# ESP32-C2 register map
Vendor: ESPRESSIF SYSTEMS (SHANGHAI) CO., LTD.; Series: ESP32 C-Series; File version: 11
CPU: RV32IMC r0p0, little endian, no MPU, no FPU, 0 interrupt priority bits
Address unit: 32 bits
Registers are 32-bit, read-write, reset 0x0 unless marked. A register's access mark holds for its fields unless they carry their own. Offsets are from the block's base; [hi:lo] are bit positions.

## ASSIST_DEBUG — Debug Assist
Base 0x600CE000
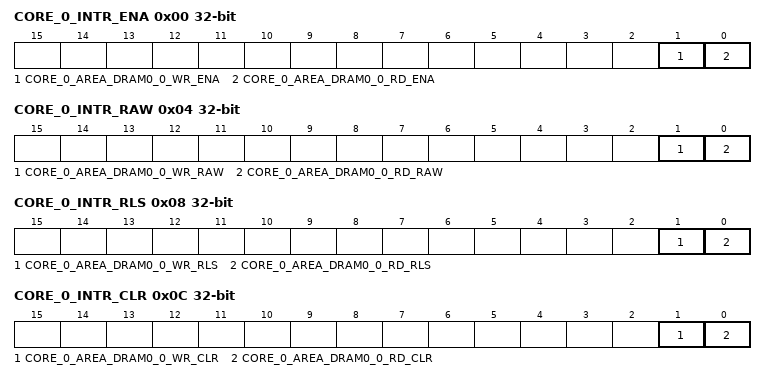
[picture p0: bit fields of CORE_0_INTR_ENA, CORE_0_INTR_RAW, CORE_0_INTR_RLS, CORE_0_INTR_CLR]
0x00 CORE_0_INTR_ENA — core0 monitor enable configuration register
  [1] CORE_0_AREA_DRAM0_0_WR_ENA — enbale sp overflow monitor
  [0] CORE_0_AREA_DRAM0_0_RD_ENA — enbale sp underlow monitor
0x04 CORE_0_INTR_RAW ro — core0 monitor interrupt status register
  [1] CORE_0_AREA_DRAM0_0_WR_RAW — sp overflow monitor interupt status register
  [0] CORE_0_AREA_DRAM0_0_RD_RAW — sp underlow monitor interrupt status register
0x08 CORE_0_INTR_RLS — core0 monitor interrupt enable register
  [1] CORE_0_AREA_DRAM0_0_WR_RLS — enbale sp overflow monitor interrupt
  [0] CORE_0_AREA_DRAM0_0_RD_RLS — enbale sp underlow monitor interrupt
0x0C CORE_0_INTR_CLR wo — core0 monitor interrupt clr register
  [1] CORE_0_AREA_DRAM0_0_WR_CLR — clr sp overflow monitor interrupt
  [0] CORE_0_AREA_DRAM0_0_RD_CLR — clr sp underlow monitor interrupt
0x10 CORE_0_SP_MIN — stack min value
  [31:0] CORE_0_SP_MIN — core0 sp region configuration regsiter
0x14 CORE_0_SP_MAX reset 0xFFFFFFFF — stack max value
  [31:0] CORE_0_SP_MAX — core0 sp pc status register
0x18 CORE_0_SP_PC ro — stack monitor pc status register
  [31:0] CORE_0_SP_PC — This regsiter stores the PC when trigger stack monitor.
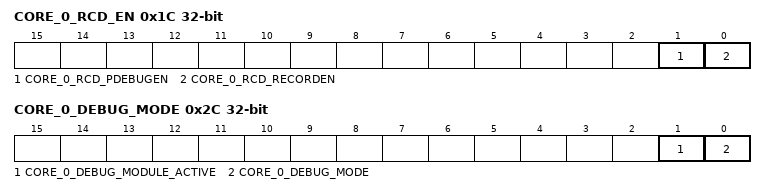
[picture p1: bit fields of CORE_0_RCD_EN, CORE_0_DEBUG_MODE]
0x1C CORE_0_RCD_EN — record enable configuration register
  [1] CORE_0_RCD_PDEBUGEN — Set 1 to enable cpu pdebug function, must set this bit can get cpu PC
  [0] CORE_0_RCD_RECORDEN — Set 1 to enable record PC
0x20 CORE_0_RCD_PDEBUGPC ro — record status regsiter
  [31:0] CORE_0_RCD_PDEBUGPC — recorded PC
0x24 CORE_0_RCD_PDEBUGSP ro — record status regsiter
  [31:0] CORE_0_RCD_PDEBUGSP — recorded sp
0x28 CORE_0_LASTPC_BEFORE_EXCEPTION ro — cpu status register
  [31:0] CORE_0_LASTPC_BEFORE_EXC — cpu's lastpc before exception
0x2C CORE_0_DEBUG_MODE ro — cpu status register
  [1] CORE_0_DEBUG_MODULE_ACTIVE — cpu debug_module active status
  [0] CORE_0_DEBUG_MODE — cpu debug mode status, 1 means cpu enter debug mode.
0x30 CLOCK_GATE reset 0x1
  [0] CLK_EN
0x1FC DATE reset 0x2106020 — version register
  [27:0] DATE

## BB — BB Peripheral
Base 0x6001D000
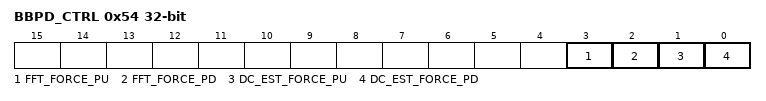
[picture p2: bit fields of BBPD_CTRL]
0x54 BBPD_CTRL — Baseband control register
  [3] FFT_FORCE_PU, [2] FFT_FORCE_PD, [1] DC_EST_FORCE_PU, [0] DC_EST_FORCE_PD

## ECC — ECC (ECC Hardware Accelerator)
Base 0x6003E000
0x0C MULT_INT_RAW ro — I2S interrupt raw register, valid in level.
  [0] CALC_DONE_INT_RAW — The raw interrupt status bit for the i2s_tx_hung_int interrupt
0x10 MULT_INT_ST ro — I2S interrupt status register.
  [0] CALC_DONE_INT_ST — The masked interrupt status bit for the i2s_rx_done_int interrupt
0x14 MULT_INT_ENA — I2S interrupt enable register.
  [0] CALC_DONE_INT_ENA — The interrupt enable bit for the i2s_rx_done_int interrupt
0x18 MULT_INT_CLR wo — I2S interrupt clear register.
  [0] CALC_DONE_INT_CLR — Set this bit to clear the i2s_rx_done_int interrupt
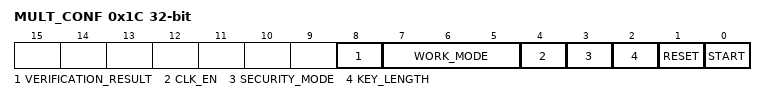
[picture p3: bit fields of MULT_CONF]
0x1C MULT_CONF access per field — I2S RX configure register
  [8] VERIFICATION_RESULT ro — Represents the verification result of ECC Accelerator, valid only when calculation is done.
  [7:5] WORK_MODE rw — Configures the work mode of ECC Accelerator.
  [4] CLK_EN rw — Configures whether to force on register clock gate.
  [3] SECURITY_MODE rw — Configures the security mode of ECC Accelerator.
  [2] KEY_LENGTH rw — Configures the key length mode bit of ECC Accelerator.
  [1] RESET wo — Configures whether to reset ECC Accelerator.
  [0] START rw — Configures whether to start calculation of ECC Accelerator.
0xFC MULT_DATE reset 0x2012230 — Version control register
  [27:0] DATE — ECC mult version control register
